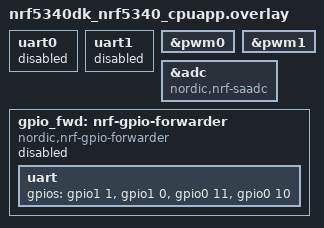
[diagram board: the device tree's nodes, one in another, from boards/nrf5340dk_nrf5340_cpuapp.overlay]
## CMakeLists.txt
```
cmake_minimum_required(VERSION 3.20.0)
find_package(Zephyr REQUIRED HINTS $ENV{ZEPHYR_BASE})

project(TIS_sensor)

target_include_directories(app PRIVATE ${CMAKE_CURRENT_LIST_DIR}/src)
target_sources(app PRIVATE src/main.c)
target_sources(app PRIVATE src/ble_service.c)
target_sources(app PRIVATE src/adc_pwm.c)
```

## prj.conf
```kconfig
CONFIG_LOG=n
CONFIG_SERIAL=n
CONFIG_GPIO=y

CONFIG_PM=y
CONFIG_PM_DEVICE=y
CONFIG_PM_DEVICE_RUNTIME=y

CONFIG_BT=y
CONFIG_BT_PERIPHERAL=y
CONFIG_BT_SETTINGS=y
CONFIG_SETTINGS=y

CONFIG_BT_SMP=n
CONFIG_BT_SETTINGS_CCC_STORE_ON_WRITE=y
CONFIG_MAIN_STACK_SIZE=2048

CONFIG_NRFX_PWM0=y
CONFIG_NRFX_PWM1=y

CONFIG_NRFX_SAADC=y

CONFIG_NRFX_TIMER0=y
CONFIG_NRFX_DPPI=y
```

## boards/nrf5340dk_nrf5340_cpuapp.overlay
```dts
uart0 {
    status = "disabled";
};
uart1 {
    status = "disabled";
};
&pwm0 {
	status = "okay";
};
&pwm1 {
	status = "okay";
};
&adc {
    status = "okay";
    compatible = "nordic,nrf-saadc";
};

gpio_fwd: nrf-gpio-forwarder {
    compatible = "nordic,nrf-gpio-forwarder";
    status = "disabled";

    uart {
        gpios = <&gpio1 1 0>, <&gpio1 0 0>, <&gpio0 11 0>, <&gpio0 10 0>;
    };
};
```

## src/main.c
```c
#include "parameter.h"
#include "adc_pwm.h"
#include "ble_service.h"

#ifndef ADC_THREAD_STACK
#define ADC_THREAD_STACK 2048
#endif
#ifndef BLE_THREAD_STACK
#define BLE_THREAD_STACK 1024
#endif
#ifndef ADC_THREAD_PRIO
#define ADC_THREAD_PRIO 4
#endif
#ifndef BLE_THREAD_PRIO
#define BLE_THREAD_PRIO 3
#endif

K_THREAD_STACK_DEFINE(adc_stack, ADC_THREAD_STACK);
K_THREAD_STACK_DEFINE(ble_stack, BLE_THREAD_STACK);
static struct k_thread adc_th;
static struct k_thread ble_th;

static void adc_thread(void *a, void *b, void *c)
{
    ARG_UNUSED(a); ARG_UNUSED(b); ARG_UNUSED(c);
    adc_pwm_init();
}

static void ble_thread(void *a, void *b, void *c)
{
    ARG_UNUSED(a); ARG_UNUSED(b); ARG_UNUSED(c);
    (void)ble_init_and_advertise();
    while (1) {
        k_sleep(K_SECONDS(1));
    }
}

void main(void)
{
    (void)bt_set_name(APP_DEVICE_NAME);

    k_thread_create(&adc_th, adc_stack, K_THREAD_STACK_SIZEOF(adc_stack),
                    adc_thread, NULL, NULL, NULL, ADC_THREAD_PRIO, 0, K_NO_WAIT);
    k_thread_name_set(&adc_th, "adc_pwm");

    k_thread_create(&ble_th, ble_stack, K_THREAD_STACK_SIZEOF(ble_stack),
                    ble_thread, NULL, NULL, NULL, BLE_THREAD_PRIO, 0, K_NO_WAIT);
    k_thread_name_set(&ble_th, "ble_core");

    while (1) {
        k_sleep(K_FOREVER);
    }
}
```

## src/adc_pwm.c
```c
#include "parameter.h"
#include "adc_pwm.h"
#include "ble_service.h"

#include <nrfx_pwm.h>
#include <nrfx_saadc.h>
#include <nrfx_timer.h>
#include <hal/nrf_timer.h>
#include <hal/nrf_saadc.h>
#include <hal/nrf_dppi.h>

#ifndef TARGET_P2P_DEFAULT
#define TARGET_P2P_DEFAULT 0u
#endif

static volatile uint16_t g_amp0 = 0;
static volatile uint16_t g_amp1 = 0;
static volatile uint16_t g_th0  = TARGET_P2P_DEFAULT;
static volatile uint16_t g_th1  = TARGET_P2P_DEFAULT;
static volatile uint8_t  g_mux  = 0;
static volatile bool     g_started = false;

static volatile uint16_t g_last_p2p0 = 0;
static volatile uint16_t g_last_p2p1 = 0;

static volatile uint16_t g_freq0_hz = (uint16_t)(PWM_FREQ0);
static volatile uint16_t g_freq1_hz = (uint16_t)(PWM_FREQ1);

static volatile uint16_t g_nsamp0 = NUM_SAMPLES0;
static volatile uint16_t g_nsamp1 = NUM_SAMPLES1;

static nrfx_pwm_t s_pwm0 = NRFX_PWM_INSTANCE(PWM_INST_IDX0);
static nrfx_pwm_t s_pwm1 = NRFX_PWM_INSTANCE(PWM_INST_IDX1);

static nrf_pwm_values_individual_t s_vals0[MAX_SAMPLES];
static nrf_pwm_values_individual_t s_vals1[MAX_SAMPLES];

static const nrfx_saadc_channel_t s_channels[] = {
    SAADC_CHANNEL_SE_ACQ(CH0_AIN, NULL, 0, 1),
    SAADC_CHANNEL_SE_ACQ(CH1_AIN, NULL, 1, 1),
};
#define SA_CH_COUNT NRFX_ARRAY_SIZE(s_channels)

static uint16_t s_sa_buf[2][CHUNK_SAMPLES * 2];

static nrfx_timer_t s_timer = NRFX_TIMER_INSTANCE(0);
#define DPPI_CH 0

static inline void gen_sine(uint16_t n, uint16_t amp, nrf_pwm_values_individual_t *dst) {
    if (n == 0) return;
    const float offset = PWM_PERIOD / 2.0f;
    for (uint16_t i = 0; i < n; i++) {
        float phase = 2.0f * (float)PI * ((float)i) / (float)n;
        int32_t v = (int32_t)((amp/2.0f) * sinf(phase) + offset);
        if (v < 0) v = 0;
        if (v > PWM_PERIOD) v = PWM_PERIOD;
        dst[i].channel_0 = (uint16_t)v;
    }
}

static inline uint16_t step_from_err(int32_t err) {
    int32_t a = (err < 0) ? -err : err;
    if (a > 200) return 10;
    if (a > 100) return 5;
    if (a > 50) return 2;
    if (a > 20)  return 1;
    return 0;
}

void adc_pwm_set_freqs(uint16_t f0_hz, uint16_t f1_hz)
{
    if (f0_hz == 0) f0_hz = g_freq0_hz;
    if (f1_hz == 0) f1_hz = g_freq1_hz;

    uint16_t n0 = (uint16_t)((100000U + (f0_hz/2)) / f0_hz);
    uint16_t n1 = (uint16_t)((100000U + (f1_hz/2)) / f1_hz);
    if (n0 < 10) {n0 = 10;} if (n0 > MAX_SAMPLES) n0 = MAX_SAMPLES;
    if (n1 < 10) {n1 = 10;} if (n1 > MAX_SAMPLES) n1 = MAX_SAMPLES;

    g_freq0_hz = f0_hz; g_nsamp0 = n0;
    g_freq1_hz = f1_hz; g_nsamp1 = n1;

    gen_sine(g_nsamp0, g_amp0, s_vals0);
    gen_sine(g_nsamp1, g_amp1, s_vals1);
    nrf_pwm_sequence_t s_seq0 = { .values.p_individual = s_vals0, .length = 4 * g_nsamp0, .repeats = 0, .end_delay = 0 };
    nrf_pwm_sequence_t s_seq1 = { .values.p_individual = s_vals1, .length = 4 * g_nsamp1, .repeats = 0, .end_delay = 0 };

    if (g_started) {
        (void)nrfx_pwm_simple_playback(&s_pwm0, &s_seq0, 1, NRFX_PWM_FLAG_LOOP);
        (void)nrfx_pwm_simple_playback(&s_pwm1, &s_seq1, 1, NRFX_PWM_FLAG_LOOP);
    } else {
        nrfx_pwm_stop(&s_pwm0, true);
        nrfx_pwm_stop(&s_pwm1, true);
    }
}

static void timer_route(uint32_t fs_hz) {
    nrfx_timer_config_t tcfg = (nrfx_timer_config_t){
        .frequency = NRF_TIMER_FREQ_1MHz,
        .mode      = NRF_TIMER_MODE_TIMER,
        .bit_width = NRF_TIMER_BIT_WIDTH_32,
        .interrupt_priority = NRFX_TIMER_DEFAULT_CONFIG_IRQ_PRIORITY,
        .p_context = NULL,
    };
    nrfx_timer_init(&s_timer, &tcfg, NULL);

    if (fs_hz == 0) fs_hz = 1;
    uint32_t cc = 1000000UL / fs_hz;
    nrfx_timer_clear(&s_timer);
    nrfx_timer_extended_compare(&s_timer, NRF_TIMER_CC_CHANNEL0, cc, NRF_TIMER_SHORT_COMPARE0_CLEAR_MASK, false);

    nrf_timer_publish_set(s_timer.p_reg, NRF_TIMER_EVENT_COMPARE0, DPPI_CH);
    nrf_saadc_subscribe_set(NRF_SAADC, NRF_SAADC_TASK_SAMPLE, DPPI_CH);
    nrf_dppi_channels_enable(NRF_DPPIC, BIT(DPPI_CH));
    nrfx_timer_enable(&s_timer);
}

static volatile bool g_amp_changed0 = false;
static volatile bool g_amp_changed1 = false;
static void saadc_handler(nrfx_saadc_evt_t const *evt) {
    switch (evt->type) {
    case NRFX_SAADC_EVT_CALIBRATEDONE:
        (void)nrfx_saadc_mode_trigger();
        break;
    case NRFX_SAADC_EVT_BUF_REQ:
        (void)nrfx_saadc_buffer_set(s_sa_buf[1], CHUNK_SAMPLES * 2);
        break;
    case NRFX_SAADC_EVT_DONE: {
        if (!g_started) {
            break;
        }

        uint16_t *buf = evt->data.done.p_buffer;
        uint16_t sz   = evt->data.done.size;

        uint16_t max0 = 0, min0 = 0xFFFF;
        uint16_t max1 = 0, min1 = 0xFFFF;

        uint16_t pairs = sz / 2;
        if (pairs > CHUNK_SAMPLES) pairs = CHUNK_SAMPLES;
        for (uint16_t i = 0; i < pairs; i++) {
            uint16_t s0 = buf[(i << 1) + 0];
            uint16_t s1 = buf[(i << 1) + 1];
            if (s0 > max0) max0 = s0;
            if (s0 < min0) min0 = s0;
            if (s1 > max1) max1 = s1;
            if (s1 < min1) min1 = s1;
        }
        uint16_t p2p0 = (max0 > min0) ? (max0 - min0) : 0;
        uint16_t p2p1 = (max1 > min1) ? (max1 - min1) : 0;
        g_last_p2p0 = p2p0;
        g_last_p2p1 = p2p1;
        
        if (g_started) {
            int32_t err0 = (int32_t)p2p0 - (int32_t)g_th0;
            int32_t err1 = (int32_t)p2p1 - (int32_t)g_th1;
            uint16_t st0 = step_from_err(err0);
            uint16_t st1 = step_from_err(err1);
            if (st0) {
                if (err0>0) { if (g_amp0 > st0) g_amp0 -= st0; }
                else         { if (g_amp0 + st0 < PWM_PERIOD) g_amp0 += st0; }
                g_amp_changed0 = true;
            }
            if (st1) {
                if (err1>0) { if (g_amp1 > st1) g_amp1 -= st1; }
                else         { if (g_amp1 + st1 < PWM_PERIOD) g_amp1 += st1; }
                g_amp_changed1 = true;
            }

            if (g_amp_changed0) {
                g_amp_changed0 = false;
                gen_sine(g_nsamp0, g_amp0, s_vals0);
                nrf_pwm_sequence_t s_seq0 = { .values.p_individual = s_vals0, .length = 4 * g_nsamp0, .repeats = 0, .end_delay = 0 };
                (void)nrfx_pwm_simple_playback(&s_pwm0, &s_seq0, 1, NRFX_PWM_FLAG_LOOP);
            }
            if (g_amp_changed1) {
                g_amp_changed1 = false;
                gen_sine(g_nsamp1, g_amp1, s_vals1);
                nrf_pwm_sequence_t s_seq1 = { .values.p_individual = s_vals1, .length = 4 * g_nsamp1, .repeats = 0, .end_delay = 0 };
                (void)nrfx_pwm_simple_playback(&s_pwm1, &s_seq1, 1, NRFX_PWM_FLAG_LOOP);
            }
        }

        if (ble_notify_enabled()) {
            (void)ble_notify_status(p2p0, p2p1,
                                    adc_pwm_get_amp0_code(),
                                    adc_pwm_get_amp1_code());
        }
        break;
    }
    default:
        break;
    }
}

void adc_pwm_set_start(bool on) { g_started = on; }
void adc_pwm_set_targets(uint16_t th0, uint16_t th1) { g_th0 = th0; g_th1 = th1; }
void adc_pwm_set_mux(uint8_t mux) { g_mux = mux & 0x01; }
uint8_t  adc_pwm_get_amp0_code(void) { uint16_t a=g_amp0; if(a>PWM_PERIOD)a=PWM_PERIOD; return (uint8_t)a; }
uint8_t  adc_pwm_get_amp1_code(void) { uint16_t a=g_amp1; if(a>PWM_PERIOD)a=PWM_PERIOD; return (uint8_t)a; }
uint16_t adc_pwm_get_last_p2p_ch0(void) { return g_last_p2p0; }
uint16_t adc_pwm_get_last_p2p_ch1(void) { return g_last_p2p1; }

void adc_pwm_init(void) {
#if defined(__ZEPHYR__)
    IRQ_CONNECT(NRFX_IRQ_NUMBER_GET(NRF_PWM_INST_GET(PWM_INST_IDX0)), IRQ_PRIO_LOWEST,
                NRFX_PWM_INST_HANDLER_GET(PWM_INST_IDX0), 0, 0);
    IRQ_CONNECT(NRFX_IRQ_NUMBER_GET(NRF_PWM_INST_GET(PWM_INST_IDX1)), IRQ_PRIO_LOWEST,
                NRFX_PWM_INST_HANDLER_GET(PWM_INST_IDX1), 0, 0);
    IRQ_CONNECT(NRFX_IRQ_NUMBER_GET(NRF_SAADC), IRQ_PRIO_LOWEST, nrfx_saadc_irq_handler, 0, 0);
#endif

    nrfx_pwm_config_t cfg0 = NRFX_PWM_DEFAULT_CONFIG(LED1_PIN, NULL, NULL, NULL);
    cfg0.top_value = PWM_PERIOD;
    cfg0.base_clock = NRF_PWM_CLK_16MHz;
    cfg0.load_mode = NRF_PWM_LOAD_INDIVIDUAL;
    (void)nrfx_pwm_init(&s_pwm0, &cfg0, NULL, &s_pwm0);

    nrfx_pwm_config_t cfg1 = NRFX_PWM_DEFAULT_CONFIG(LED2_PIN, NULL, NULL, NULL);
    cfg1.top_value = PWM_PERIOD;
    cfg1.base_clock = NRF_PWM_CLK_16MHz;
    cfg1.load_mode = NRF_PWM_LOAD_INDIVIDUAL;
    (void)nrfx_pwm_init(&s_pwm1, &cfg1, NULL, &s_pwm1);

    gen_sine(NUM_SAMPLES0, g_amp0, s_vals0);
    gen_sine(NUM_SAMPLES1, g_amp1, s_vals1);
    nrf_pwm_sequence_t s_seq0 = { .values.p_individual = s_vals0, .length = 4 * g_nsamp0, .repeats = 0, .end_delay = 0 };
    nrf_pwm_sequence_t s_seq1 = { .values.p_individual = s_vals1, .length = 4 * g_nsamp1, .repeats = 0, .end_delay = 0 };
    if (g_started) {
        (void)nrfx_pwm_simple_playback(&s_pwm0, &s_seq0, 1, NRFX_PWM_FLAG_LOOP);
        (void)nrfx_pwm_simple_playback(&s_pwm1, &s_seq1, 1, NRFX_PWM_FLAG_LOOP);
    } else {
        nrfx_pwm_stop(&s_pwm0, true);
        nrfx_pwm_stop(&s_pwm1, true);
    }

    (void)nrfx_saadc_init(NRFX_SAADC_DEFAULT_CONFIG_IRQ_PRIORITY);
    (void)nrfx_saadc_channels_config(s_channels, SA_CH_COUNT);

    nrfx_saadc_adv_config_t adv = NRFX_SAADC_DEFAULT_ADV_CONFIG;
    adv.internal_timer_cc = 0;
    adv.start_on_end = true;
    uint32_t mask = nrfx_saadc_channels_configured_get();
    (void)nrfx_saadc_advanced_mode_set(mask, ADC_RESOLUTION, &adv, saadc_handler);

    (void)nrfx_saadc_buffer_set(s_sa_buf[0], CHUNK_SAMPLES * 2);
    (void)nrfx_saadc_buffer_set(s_sa_buf[1], CHUNK_SAMPLES * 2);

    timer_route(SAADC_SAMPLE_FREQUENCY);

    (void)nrfx_saadc_offset_calibrate(saadc_handler);

    nrf_gpio_cfg_output(GPIO_PIN0);
    nrf_gpio_cfg_output(GPIO_PIN1);
    nrf_gpio_cfg_output(GPIO_PWR);
    
    nrf_gpio_pin_clear(GPIO_PIN0);
    nrf_gpio_pin_clear(GPIO_PIN1);
    nrf_gpio_pin_clear(GPIO_PWR);
    
    while (1) {
        if (g_mux == 0) { nrf_gpio_pin_clear(GPIO_PIN0); nrf_gpio_pin_clear(GPIO_PIN1); }
        else            { nrf_gpio_pin_set(GPIO_PIN0); nrf_gpio_pin_set(GPIO_PIN1); }

        nrf_gpio_pin_set(GPIO_PWR);
        k_sleep(K_MSEC(1));
        nrf_gpio_pin_clear(GPIO_PWR);
        k_sleep(K_MSEC(10));
    }
}
```

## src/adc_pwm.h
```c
#pragma once
#include <stdint.h>
#include <stdbool.h>

#ifdef __cplusplus
extern "C" {
#endif

void adc_pwm_set_start(bool on);
void adc_pwm_set_targets(uint16_t th0, uint16_t th1);
void adc_pwm_set_mux(uint8_t mux);

uint16_t adc_pwm_get_last_p2p_ch0(void);
uint16_t adc_pwm_get_last_p2p_ch1(void);

uint8_t  adc_pwm_get_amp0_code(void);
uint8_t  adc_pwm_get_amp1_code(void);

void adc_pwm_set_freqs(uint16_t f0_hz, uint16_t f1_hz);

#ifdef __cplusplus
}
#endif
```

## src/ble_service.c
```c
#include "parameter.h"
#include "adc_pwm.h"
#include "ble_service.h"

#include <zephyr/bluetooth/bluetooth.h>
#include <zephyr/bluetooth/conn.h>
#include <zephyr/bluetooth/gatt.h>
#include <zephyr/bluetooth/uuid.h>
#include <zephyr/bluetooth/hci.h>

#if Device == 1
static struct bt_uuid_128 SVC_UUID  = BT_UUID_INIT_128(
    BT_UUID_128_ENCODE(0x4F191C00,0x5A23,0x4A82,0x8F3D,0x6C9E4E9B0000ULL)
);
static struct bt_uuid_128 TX_CHR_UUID= BT_UUID_INIT_128(
    BT_UUID_128_ENCODE(0x4F191C01,0x5A23,0x4A82,0x8F3D,0x6C9E4E9B0000ULL)
);
static struct bt_uuid_128 RX_CHR_UUID= BT_UUID_INIT_128(
    BT_UUID_128_ENCODE(0x4F191C02,0x5A23,0x4A82,0x8F3D,0x6C9E4E9B0000ULL)
);
#endif

static struct bt_conn *g_conn;
static atomic_t g_ccc_on = ATOMIC_INIT(0);

static ssize_t rd_fn(struct bt_conn *c, const struct bt_gatt_attr *a,
                     void *buf, uint16_t len, uint16_t off)
{
    uint8_t pkt[6];
    uint16_t p2p0 = adc_pwm_get_last_p2p_ch0();
    uint16_t p2p1 = adc_pwm_get_last_p2p_ch1();

    pkt[0] = (uint8_t)(p2p0 & 0xFF);
    pkt[1] = (uint8_t)((p2p0 >> 8) & 0xFF);
    pkt[2] = (uint8_t)(p2p1 & 0xFF);
    pkt[3] = (uint8_t)((p2p1 >> 8) & 0xFF);
    pkt[4] = adc_pwm_get_amp0_code();
    pkt[5] = adc_pwm_get_amp1_code();
    return bt_gatt_attr_read(c, a, buf, len, off, pkt, sizeof(pkt));
}

static ssize_t wr_fn(struct bt_conn *c, const struct bt_gatt_attr *a,
                     const void *buf, uint16_t len, uint16_t offset, uint8_t flags)
{
    if (offset != 0 || len < 6)
        return BT_GATT_ERR(BT_ATT_ERR_INVALID_ATTRIBUTE_LEN);

    const uint8_t *p = (const uint8_t *)buf;
    bool start = (p[0] & 0x10) ? true : false;
    uint16_t th0 = (uint16_t)(p[1] | (p[2] << 8));
    uint16_t th1 = (uint16_t)(p[3] | (p[4] << 8));
    uint8_t mux   = p[5] & 0x01;

    adc_pwm_set_targets(th0, th1);
    adc_pwm_set_start(start);
    adc_pwm_set_mux(mux);

    if (mux == 0) { nrf_gpio_pin_clear(GPIO_PIN0); nrf_gpio_pin_clear(GPIO_PIN1); }
    else          { nrf_gpio_pin_set(GPIO_PIN0); nrf_gpio_pin_set(GPIO_PIN1); }

    if (len >= 10) {
        uint16_t f0 = (uint16_t)(p[6] | (p[7] << 8));
        uint16_t f1 = (uint16_t)(p[8] | (p[9] << 8));
        if (f0) {
            adc_pwm_set_freqs(f0, f1);
        }
    }

    return len;
}

static void ccc_changed(const struct bt_gatt_attr *attr, uint16_t value)
{
    bool on = (value & BT_GATT_CCC_NOTIFY) != 0;
    atomic_set(&g_ccc_on, on);
}

BT_GATT_SERVICE_DEFINE(tis_svc,
    BT_GATT_PRIMARY_SERVICE(&SVC_UUID),

    BT_GATT_CHARACTERISTIC(&RX_CHR_UUID.uuid,
        BT_GATT_CHRC_WRITE | BT_GATT_CHRC_WRITE_WITHOUT_RESP,
        BT_GATT_PERM_WRITE, NULL, wr_fn, NULL),

    BT_GATT_CHARACTERISTIC(&TX_CHR_UUID.uuid,
        BT_GATT_CHRC_READ | BT_GATT_CHRC_NOTIFY,
        BT_GATT_PERM_READ, rd_fn, NULL, NULL),
    BT_GATT_CCC(ccc_changed, BT_GATT_PERM_READ | BT_GATT_PERM_WRITE)
);

static const struct bt_gatt_attr *rd_attr_ptr(void)
{
    return &tis_svc.attrs[4];
}

static int adv_start_safe(void);

static void connected(struct bt_conn *c, uint8_t err)
{
    if (err) return;
    g_conn = bt_conn_ref(c);

    (void)bt_conn_le_param_update(c, &(struct bt_le_conn_param){
        .interval_min = REQ_CONN_INTERVAL_MIN,
        .interval_max = REQ_CONN_INTERVAL_MAX,
        .latency      = REQ_CONN_LATENCY,
        .timeout      = REQ_CONN_TIMEOUT,
    });
}

static void disconnected(struct bt_conn *c, uint8_t reason)
{
    if (g_conn) { bt_conn_unref(g_conn); g_conn = NULL; }
    atomic_set(&g_ccc_on, 0);
    (void)adv_start_safe();
}

BT_CONN_CB_DEFINE(conn_cb) = {
    .connected = connected,
    .disconnected = disconnected
};

static const struct bt_data ad[] = {
    BT_DATA_BYTES(BT_DATA_FLAGS, (BT_LE_AD_GENERAL | BT_LE_AD_NO_BREDR)),
    BT_DATA(BT_DATA_UUID128_ALL, SVC_UUID.val, sizeof(SVC_UUID.val))
};
static const struct bt_data sd[] = {
    BT_DATA(BT_DATA_NAME_COMPLETE, APP_DEVICE_NAME, strlen(APP_DEVICE_NAME)),
};

static int adv_start_safe(void)
{
    int err = bt_le_adv_start(BT_LE_ADV_CONN, ad, ARRAY_SIZE(ad), sd, ARRAY_SIZE(sd));
    if (err == -EALREADY) {
        (void)bt_le_adv_stop();
        err = bt_le_adv_start(BT_LE_ADV_CONN, ad, ARRAY_SIZE(ad), sd, ARRAY_SIZE(sd));
    }
    return err;
}

static void bt_ready_cb(int err)
{
    if (err) return;
#if defined(CONFIG_SETTINGS)
    settings_load();
#endif
    (void)adv_start_safe();
}

int ble_init_and_advertise(void)
{
    (void)bt_set_name(APP_DEVICE_NAME);
    int rc = bt_enable(bt_ready_cb);
    if (rc == -EALREADY) (void)adv_start_safe();
    return (rc && rc != -EALREADY) ? rc : 0;
}

bool ble_notify_enabled(void)
{
    return (g_conn && atomic_get(&g_ccc_on));
}

int ble_notify_status(uint8_t p2p0, uint16_t p2p1, uint8_t amp0, uint8_t amp1)
{
    if (!ble_notify_enabled()) return -EACCES;
    uint8_t pkt[6] = {
        (uint8_t)(p2p0 & 0xFF), (uint8_t)((p2p0 >> 8) & 0xFF),
        (uint8_t)(p2p1 & 0xFF), (uint8_t)((p2p1 >> 8) & 0xFF),
        amp0, amp1
    };
    struct bt_gatt_notify_params np = {
        .attr = rd_attr_ptr(),
        .data = pkt,
        .len  = sizeof(pkt),
    };
    return bt_gatt_notify_cb(g_conn, &np);
}
```

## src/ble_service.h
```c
#pragma once
#include <stdint.h>
#include <stdbool.h>

#ifdef __cplusplus
extern "C" {
#endif

int  ble_init_and_advertise(void);
bool ble_notify_enabled(void);
int  ble_notify_status(uint8_t p2p0, uint16_t p2p1, uint8_t amp0, uint8_t amp1);
void adc_pwm_set_freqs(uint16_t f0_hz, uint16_t f1_hz);

#ifdef __cplusplus
}
#endif
```

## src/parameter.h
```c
#ifndef PARAMETER_H__
#define PARAMETER_H__

#include <zephyr/kernel.h>
#include <math.h>
#include <string.h>
#include <zephyr/sys/byteorder.h>
#include <hal/nrf_gpio.h>

#define Device 1

#if Device == 1
#define APP_DEVICE_NAME "TIS_System"
#endif

#define GPIO_PIN0 5
#define GPIO_PIN1 29
#define GPIO_PWR  32

#define PWM_INST_IDX0 0
#define LED1_PIN      21

#define PWM_INST_IDX1 1
#define LED2_PIN      40

#define MAX_SAMPLES     200
#define PWM_PERIOD      160
#define PI              3.14159265358979323846f
#define PWM_FREQ0       1000.0f
#define NUM_SAMPLES0    100
#define PWM_FREQ1       1010.0f
#define NUM_SAMPLES1    99

#define ANALOG_INPUT_TO_SAADC_AIN(x) ((x) + 1)
#define ANALOG_INPUT_TO_COMP_AIN(x)   (x)
#define ANALOG_INPUT_A0 2
#define CH0_AIN ANALOG_INPUT_TO_SAADC_AIN(ANALOG_INPUT_A0)
#define ANALOG_INPUT_A1 3
#define CH1_AIN ANALOG_INPUT_TO_SAADC_AIN(ANALOG_INPUT_A1)

#define SAADC_CHANNEL_SE_ACQ(_pin_p, _pin_n, _index, _mode) \
{ .channel_config = { \
    .resistor_p = NRF_SAADC_RESISTOR_DISABLED, \
    .resistor_n = NRF_SAADC_RESISTOR_DISABLED, \
    .gain       = NRF_SAADC_GAIN1_4, \
    .reference  = NRF_SAADC_REFERENCE_VDD4, \
    .acq_time   = NRF_SAADC_ACQTIME_3US, \
    .mode       = NRF_SAADC_MODE_SINGLE_ENDED, \
    .burst      = NRF_SAADC_BURST_DISABLED, \
  }, \
  .pin_p = (nrf_saadc_input_t)_pin_p, \
  .pin_n = NRF_SAADC_INPUT_DISABLED, \
  .channel_index = _index, \
}

#define ADC_RESOLUTION       NRF_SAADC_RESOLUTION_12BIT
#define CHUNK_POOL_SIZE 24
#define INTERNAL_TIMER_FREQ      16000000UL
#define SAADC_SAMPLE_FREQUENCY   20000UL
#define INTERNAL_TIMER_CC (INTERNAL_TIMER_FREQ / SAADC_SAMPLE_FREQUENCY)

#define CHUNK_SAMPLES 2000U
#define CHUNK_BYTES   (CHUNK_SAMPLES * sizeof(uint16_t))

#ifndef NRFX_TIMER_DEFAULT_CONFIG_IRQ_PRIORITY
#define NRFX_TIMER_DEFAULT_CONFIG_IRQ_PRIORITY 7
#endif

#define REQ_CONN_INTERVAL_MIN  6
#define REQ_CONN_INTERVAL_MAX 24
#define REQ_CONN_LATENCY       0
#define REQ_CONN_TIMEOUT     400

#endif
```
